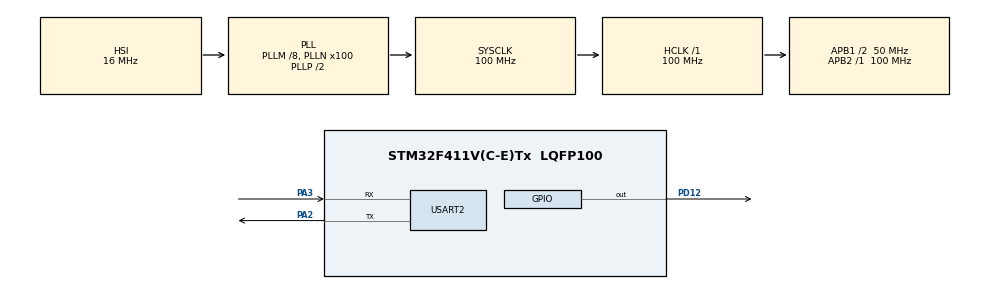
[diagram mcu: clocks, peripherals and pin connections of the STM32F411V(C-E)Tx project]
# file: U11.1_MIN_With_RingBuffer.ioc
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Mcu.Family=STM32F4
Mcu.Name=STM32F411V(C-E)Tx
Mcu.Package=LQFP100
NVIC.PriorityGroup=NVIC_PRIORITYGROUP_4
NVIC.USART2_IRQn=true\:0\:0\:false\:false\:true\:true\:true
PA13.Mode=Serial_Wire
PA13.Signal=SYS_JTMS-SWDIO
PA14.Mode=Serial_Wire
PA14.Signal=SYS_JTCK-SWCLK
PA2.Mode=Asynchronous
PA2.Signal=USART2_TX
PA3.Mode=Asynchronous
PA3.Signal=USART2_RX
PD12.Signal=GPIO_Output
PH0\ -\ OSC_IN.Mode=HSE-External-Clock-Source
PH0\ -\ OSC_IN.Signal=RCC_OSC_IN
PH1\ -\ OSC_OUT.Mode=HSE-External-Clock-Source
PH1\ -\ OSC_OUT.Signal=RCC_OSC_OUT
ProjectManager.HeapSize=0x200
ProjectManager.StackSize=0x400
ProjectManager.TargetToolchain=STM32CubeIDE
RCC.48MHZClocksFreq_Value=50000000
RCC.AHBFreq_Value=100000000
RCC.APB1CLKDivider=RCC_HCLK_DIV2
RCC.APB1Freq_Value=50000000
RCC.APB1TimFreq_Value=100000000
RCC.APB2Freq_Value=100000000
RCC.APB2TimFreq_Value=100000000
RCC.CortexFreq_Value=100000000
RCC.HCLKFreq_Value=100000000
RCC.HSE_VALUE=25000000
RCC.HSI_VALUE=16000000
RCC.LSE_VALUE=32768
RCC.PLLM=8
RCC.PLLN=100
RCC.SYSCLKFreq_VALUE=100000000
RCC.SYSCLKSource=RCC_SYSCLKSOURCE_PLLCLK
RCC.VCOOutputFreq_Value=200000000
USART2.VirtualMode=VM_ASYNC
board=custom

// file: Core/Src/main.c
/* USER CODE BEGIN Header */
/**
  ******************************************************************************
  * @file           : main.c
  * @brief          : Main program body
  ******************************************************************************
  * @attention
  *
  * Copyright (c) 2022 STMicroelectronics.
  * All rights reserved.
  *
  * This software is licensed under terms that can be found in the LICENSE file
  * in the root directory of this software component.
  * If no LICENSE file comes with this software, it is provided AS-IS.
  *
  ******************************************************************************
  */
/* USER CODE END Header */
#include "main.h"

/* USER CODE BEGIN Includes */

#include "uart.h"
#include "min.h"

/* USER CODE END Includes */

UART_HandleTypeDef huart2;

void SystemClock_Config(void);
static void MX_GPIO_Init(void);
static void MX_USART2_UART_Init(void);

/* USER CODE BEGIN 0 */

uint8_t Rx_Buffer;
void HAL_UART_RxCpltCallback(UART_HandleTypeDef *huart){
	if(huart->Instance == huart2.Instance){
		UART_Receive(Rx_Buffer);
		HAL_UART_Receive_IT(huart, &Rx_Buffer, 1);
	}
}

struct min_context min_ctx;

void min_application_handler(uint8_t min_id, uint8_t const *min_payload, uint8_t len_payload, uint8_t port){
	HAL_GPIO_WritePin(GPIOD, GPIO_PIN_12, (GPIO_PinState)min_payload[0]);
}

uint32_t min_time_ms(void){
	return HAL_GetTick();
}

uint16_t min_tx_space(uint8_t port){
	return 512;
}

void min_tx_byte(uint8_t port, uint8_t byte){
	USART2->DR = byte;
	while(!(USART2->SR & USART_SR_TC));
}

void min_tx_start(uint8_t port){

}

void min_tx_finished(uint8_t port){

}

/* USER CODE END 0 */

int main(void)
{

  /* MCU Configuration--------------------------------------------------------*/

  /* Reset of all peripherals, Initializes the Flash interface and the Systick. */
  HAL_Init();

  /* Configure the system clock */
  SystemClock_Config();

  /* Initialize all configured peripherals */
  MX_GPIO_Init();
  MX_USART2_UART_Init();
  /* USER CODE BEGIN 2 */

  UART_Init();
  HAL_UART_Receive_IT(&huart2, &Rx_Buffer, 1);
  min_init_context(&min_ctx, 0);
  HAL_Delay(1000);

  /* USER CODE END 2 */

  /* Infinite loop */
  while (1)
  {

    /* USER CODE BEGIN 3 */

	  uint8_t t_data = 0;
	  uint8_t len = 0;
	  if(UART_Available() != 0){
		  t_data = UART_Read();
		  len = 1;
	  }
	  min_poll(&min_ctx, &t_data, len);
//	  uint8_t t_buff[] = {0x05, 0x55, 0x55, 0x55};
//	  min_send_frame(&min_ctx, 0, t_buff, sizeof(t_buff));
//	  HAL_Delay(1000);
  }
  /* USER CODE END 3 */
}

void SystemClock_Config(void)
{
  RCC_OscInitTypeDef RCC_OscInitStruct = {0};
  RCC_ClkInitTypeDef RCC_ClkInitStruct = {0};

  /** Configure the main internal regulator output voltage
  */
  __HAL_RCC_PWR_CLK_ENABLE();
  __HAL_PWR_VOLTAGESCALING_CONFIG(PWR_REGULATOR_VOLTAGE_SCALE1);
  /** Initializes the RCC Oscillators according to the specified parameters
  * in the RCC_OscInitTypeDef structure.
  */
  RCC_OscInitStruct.OscillatorType = RCC_OSCILLATORTYPE_HSI;
  RCC_OscInitStruct.HSIState = RCC_HSI_ON;
  RCC_OscInitStruct.HSICalibrationValue = RCC_HSICALIBRATION_DEFAULT;
  RCC_OscInitStruct.PLL.PLLState = RCC_PLL_ON;
  RCC_OscInitStruct.PLL.PLLSource = RCC_PLLSOURCE_HSI;
  RCC_OscInitStruct.PLL.PLLM = 8;
  RCC_OscInitStruct.PLL.PLLN = 100;
  RCC_OscInitStruct.PLL.PLLP = RCC_PLLP_DIV2;
  RCC_OscInitStruct.PLL.PLLQ = 4;
  if (HAL_RCC_OscConfig(&RCC_OscInitStruct) != HAL_OK)
  {
    Error_Handler();
  }
  /** Initializes the CPU, AHB and APB buses clocks
  */
  RCC_ClkInitStruct.ClockType = RCC_CLOCKTYPE_HCLK|RCC_CLOCKTYPE_SYSCLK
                              |RCC_CLOCKTYPE_PCLK1|RCC_CLOCKTYPE_PCLK2;
  RCC_ClkInitStruct.SYSCLKSource = RCC_SYSCLKSOURCE_PLLCLK;
  RCC_ClkInitStruct.AHBCLKDivider = RCC_SYSCLK_DIV1;
  RCC_ClkInitStruct.APB1CLKDivider = RCC_HCLK_DIV2;
  RCC_ClkInitStruct.APB2CLKDivider = RCC_HCLK_DIV1;

  if (HAL_RCC_ClockConfig(&RCC_ClkInitStruct, FLASH_LATENCY_3) != HAL_OK)
  {
    Error_Handler();
  }
}

static void MX_USART2_UART_Init(void)
{

  huart2.Instance = USART2;
  huart2.Init.BaudRate = 115200;
  huart2.Init.WordLength = UART_WORDLENGTH_8B;
  huart2.Init.StopBits = UART_STOPBITS_1;
  huart2.Init.Parity = UART_PARITY_NONE;
  huart2.Init.Mode = UART_MODE_TX_RX;
  huart2.Init.HwFlowCtl = UART_HWCONTROL_NONE;
  huart2.Init.OverSampling = UART_OVERSAMPLING_16;
  if (HAL_UART_Init(&huart2) != HAL_OK)
  {
    Error_Handler();
  }

}

static void MX_GPIO_Init(void)
{
  GPIO_InitTypeDef GPIO_InitStruct = {0};

  /* GPIO Ports Clock Enable */
  __HAL_RCC_GPIOH_CLK_ENABLE();
  __HAL_RCC_GPIOA_CLK_ENABLE();
  __HAL_RCC_GPIOD_CLK_ENABLE();

  /*Configure GPIO pin Output Level */
  HAL_GPIO_WritePin(GPIOD, GPIO_PIN_12, GPIO_PIN_RESET);

  /*Configure GPIO pin : PD12 */
  GPIO_InitStruct.Pin = GPIO_PIN_12;
  GPIO_InitStruct.Mode = GPIO_MODE_OUTPUT_PP;
  GPIO_InitStruct.Pull = GPIO_NOPULL;
  GPIO_InitStruct.Speed = GPIO_SPEED_FREQ_LOW;
  HAL_GPIO_Init(GPIOD, &GPIO_InitStruct);

}

void Error_Handler(void)
{
  __disable_irq();
  while (1)
  {
  }
}
